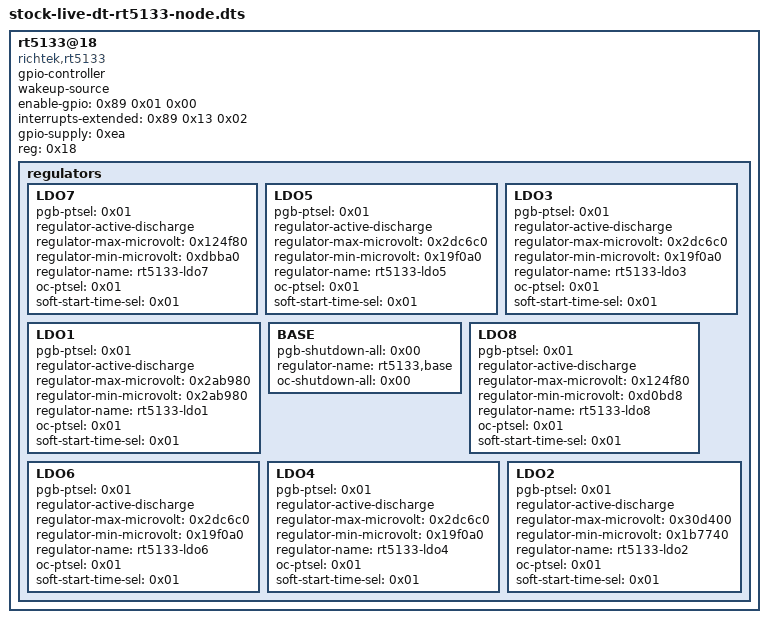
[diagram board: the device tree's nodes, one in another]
// /soc/i2c@11280000/rt5133@18 from live /proc/device-tree (workspace/usmart-audit/dt/live-merged.dts)
			rt5133@18 {
				gpio-controller;
				wakeup-source;
				enable-gpio = <0x89 0x01 0x00>;
				interrupts-extended = <0x89 0x13 0x02>;
				gpio-supply = <0xea>;
				compatible = "richtek,rt5133";
				status = "ok";
				reg = <0x18>;
				phandle = <0x14c>;
				#gpio-cells = <0x02>;

				regulators {

					LDO7 {
						pgb-ptsel = <0x01>;
						regulator-active-discharge;
						regulator-max-microvolt = <0x124f80>;
						regulator-min-microvolt = <0xdbba0>;
						regulator-name = "rt5133-ldo7";
						oc-ptsel = <0x01>;
						phandle = <0x250>;
						soft-start-time-sel = <0x01>;
					};

					LDO5 {
						pgb-ptsel = <0x01>;
						regulator-active-discharge;
						regulator-max-microvolt = <0x2dc6c0>;
						regulator-min-microvolt = <0x19f0a0>;
						regulator-name = "rt5133-ldo5";
						oc-ptsel = <0x01>;
						phandle = <0x24e>;
						soft-start-time-sel = <0x01>;
					};

					LDO3 {
						pgb-ptsel = <0x01>;
						regulator-active-discharge;
						regulator-max-microvolt = <0x2dc6c0>;
						regulator-min-microvolt = <0x19f0a0>;
						regulator-name = "rt5133-ldo3";
						oc-ptsel = <0x01>;
						phandle = <0x24c>;
						soft-start-time-sel = <0x01>;
					};

					LDO1 {
						pgb-ptsel = <0x01>;
						regulator-active-discharge;
						regulator-max-microvolt = <0x2ab980>;
						regulator-min-microvolt = <0x2ab980>;
						regulator-name = "rt5133-ldo1";
						oc-ptsel = <0x01>;
						phandle = <0xea>;
						soft-start-time-sel = <0x01>;
					};

					BASE {
						pgb-shutdown-all = <0x00>;
						regulator-name = "rt5133,base";
						oc-shutdown-all = <0x00>;
					};

					LDO8 {
						pgb-ptsel = <0x01>;
						regulator-active-discharge;
						regulator-max-microvolt = <0x124f80>;
						regulator-min-microvolt = <0xd0bd8>;
						regulator-name = "rt5133-ldo8";
						oc-ptsel = <0x01>;
						phandle = <0x251>;
						soft-start-time-sel = <0x01>;
					};

					LDO6 {
						pgb-ptsel = <0x01>;
						regulator-active-discharge;
						regulator-max-microvolt = <0x2dc6c0>;
						regulator-min-microvolt = <0x19f0a0>;
						regulator-name = "rt5133-ldo6";
						oc-ptsel = <0x01>;
						phandle = <0x24f>;
						soft-start-time-sel = <0x01>;
					};

					LDO4 {
						pgb-ptsel = <0x01>;
						regulator-active-discharge;
						regulator-max-microvolt = <0x2dc6c0>;
						regulator-min-microvolt = <0x19f0a0>;
						regulator-name = "rt5133-ldo4";
						oc-ptsel = <0x01>;
						phandle = <0x24d>;
						soft-start-time-sel = <0x01>;
					};

					LDO2 {
						pgb-ptsel = <0x01>;
						regulator-active-discharge;
						regulator-max-microvolt = <0x30d400>;
						regulator-min-microvolt = <0x1b7740>;
						regulator-name = "rt5133-ldo2";
						oc-ptsel = <0x01>;
						phandle = <0x24b>;
						soft-start-time-sel = <0x01>;
					};
				};
			};
